# AVR32DU32 device description
Architecture: AVR8X; Family: AVR
Registers are 8-bit, read-write, reset 0x0 unless marked. A register's access mark holds for its fields unless they carry their own. Offsets are from the block's base; [hi:lo] are bit positions; {n}, {i} and the like mark numbered series; 'fields as' and 'values as' point back to an identical list.

## GPR — General Purpose Registers
Instances: GPR 0x001C
{0x0+i} GPR{i} reset not defined (i=0..3) — General Purpose Register {i}

## LOCK — Lockbits
Instances: LOCK 0x1040
0x00 KEY 32-bit reset 0x5CC5C55C — Lock Key Bits
  [31:0] KEY — Lock Key
    0x5CC5C55C=NOLOCK (No locks); 0xA33A3AA3=RWLOCK (Read and write lock)

## NVMCTRL — Non-volatile Memory Controller
Instances: NVMCTRL 0x1000
0x00 CTRLA — Control A
  [6:0] CMD — Command
    0=NONE (No Command); 1=NOOP (No Operation); 2=FLWR (Flash Write); 8=FLPER (Flash Page Erase); 9=FLMPER2 (Flash Multi-Page Erase 2 pages); 10=FLMPER4 (Flash Multi-Page Erase 4 pages); 11=FLMPER8 (Flash Multi-Page Erase 8 pages); 12=FLMPER16 (Flash Multi-Page Erase 16 pages); 13=FLMPER32 (Flash Multi-Page Erase 32 pages); 18=EEWR (EEPROM Write); 19=EEERWR (EEPROM Erase and Write); 24=EEBER (EEPROM Byte Erase); 25=EEMBER2 (EEPROM Multi-Byte Erase 2 bytes); 26=EEMBER4 (EEPROM Multi-Byte Erase 4 bytes); 27=EEMBER8 (EEPROM Multi-Byte Erase 8 bytes); 28=EEMBER16 (EEPROM Multi-Byte Erase 16 bytes); 29=EEMBER32 (EEPROM Multi-Byte Erase 32 bytes); 32=CHER (Chip Erase Command); 48=EECHER (EEPROM Erase Command)
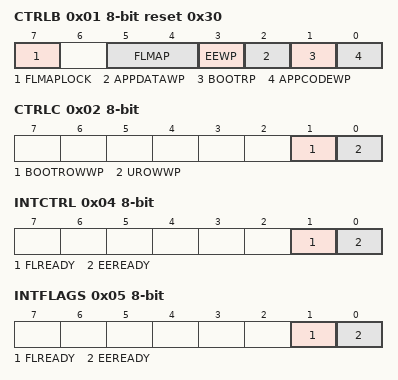
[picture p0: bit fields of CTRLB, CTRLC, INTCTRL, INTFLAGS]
0x01 CTRLB reset 0x30 — Control B
  [7] FLMAPLOCK — Flash Mapping Lock
  [5:4] FLMAP — Flash Mapping in Data space
    {v}=SECTION{v} (Flash section {v}) (v=0..3)
  [3] EEWP — EEPROM Write Protect
  [2] APPDATAWP — Application Data Write Protect
  [1] BOOTRP — Boot Read Protect
  [0] APPCODEWP — Application Code Write Protect
0x02 CTRLC — Control C
  [1] BOOTROWWP — Boot Row Write Protect
  [0] UROWWP — User Row Write Protect
0x04 INTCTRL — Interrupt Control
  [1] FLREADY — Flash Ready
  [0] EEREADY — EEPROM Ready
0x05 INTFLAGS — Interrupt Flags
  [1] FLREADY — Flash Ready
  [0] EEREADY — EEPROM Ready
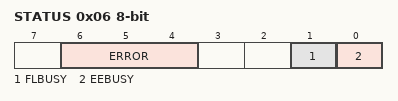
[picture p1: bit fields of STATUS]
0x06 STATUS ro
  [6:4] ERROR — Write error
    0=NOERROR; 1=INVALIDCMD (Write command not selected or not valid); 2=WRITEPROTECT (Write to section not allowed); 3=CMDCOLLISION (Selecting new write command while programming is ongoing)
  [1] FLBUSY — Flash busy
  [0] EEBUSY — EEPROM busy
0x08 DATA 32-bit
0x0C ADDR 32-bit reset not defined — Address

## PORT — I/O Ports
Instances: PORTA 0x0400, PORTC 0x0440, PORTD 0x0460, PORTF 0x04A0
0x00 DIR — Data Direction
0x01 DIRSET — Data Direction Set
0x02 DIRCLR — Data Direction Clear
0x03 DIRTGL — Data Direction Toggle
0x04 OUT — Output Value
0x05 OUTSET — Output Value Set
0x06 OUTCLR — Output Value Clear
0x07 OUTTGL — Output Value Toggle
0x08 IN — Input Value
0x09 INTFLAGS — Interrupt Flags
  [7:0] INT — Pin Interrupt Flag
0x0A PORTCTRL — Port Control
  [0] SRL — Slew Rate Limit Enable
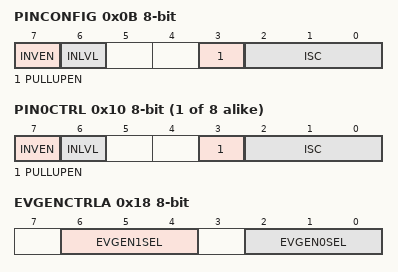
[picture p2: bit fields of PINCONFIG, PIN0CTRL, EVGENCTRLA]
0x0B PINCONFIG — Pin Control Config
  [7] INVEN — Inverted I/O Enable
  [6] INLVL — Input Level Select
    0=ST (Schmitt-Trigger input level); 1=TTL (TTL Input level)
  [3] PULLUPEN — Pullup enable
  [2:0] ISC — Input/Sense Configuration
    0=INTDISABLE (Interrupt disabled but input buffer enabled); 1=BOTHEDGES (Sense Both Edges); 2=RISING (Sense Rising Edge); 3=FALLING (Sense Falling Edge); 4=INPUT_DISABLE (Digital Input Buffer disabled); 5=LEVEL (Sense low Level)
0x0C PINCTRLUPD — Pin Control Update
0x0D PINCTRLSET — Pin Control Set
0x0E PINCTRLCLR — Pin Control Clear
{0x10+i} PIN{i}CTRL (i=0..7) — Pin {i} Control
  fields as PINCONFIG
0x18 EVGENCTRLA — Event Generation Control A
  [6:4] EVGEN1SEL — Event Generator 1 Select
    {v}=PIN{v} (Pin {v} used as event generator) (v=0..7)
  [2:0] EVGEN0SEL — Event Generator 0 Select
    {v}=PIN{v} (Pin {v} used as event generator) (v=0..7)

## PORTMUX — Port Multiplexer
Instances: PORTMUX 0x05E0
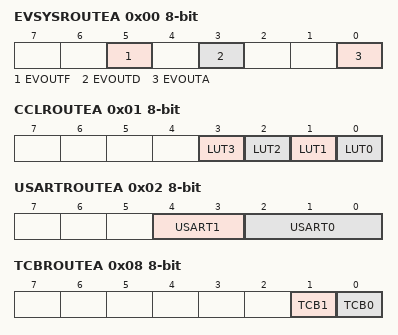
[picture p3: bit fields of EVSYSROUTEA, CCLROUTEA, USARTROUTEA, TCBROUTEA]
0x00 EVSYSROUTEA
  [5] EVOUTF — Event Output F
    0=DEFAULT (EVOUTF: PF2); 1=ALT1 (EVOUTF: PF7)
  [3] EVOUTD — Event Output D
    0=DEFAULT (EVOUTD: PD2); 1=ALT1 (EVOUTD: PD7)
  [0] EVOUTA — Event Output A
    0=DEFAULT (EVOUTA: PA2); 1=ALT1 (EVOUTA: PA7)
0x01 CCLROUTEA
  [3] LUT3 — CCL Look-Up Table 3 Signals
    0=DEFAULT (In: PF0, PF1, PF2, Out: PF3)
  [2] LUT2 — CCL Look-Up Table 2 Signals
    0=DEFAULT (In: PD0, PD1, PD2, Out: PD3); 1=ALT1 (In: PD0, PD1, PD2, Out: PD6)
  [1] LUT1 — CCL Look-Up Table 1 Signals
    0=DEFAULT (In: -, -, -, Out: PC3)
  [0] LUT0 — CCL Look-Up Table 0 Signals
    0=DEFAULT (In: PA0, PA1, PA2, Out: PA3); 1=ALT1 (In: PA0, PA1, PA2, Out: PA6)
0x02 USARTROUTEA
  [4:3] USART1 — USART1 Signals
    0=DEFAULT (Not connected to any pins); 2=ALT2 (TxD: PD6, RxD: PD7, XCK: -, XDIR: -)
  [2:0] USART0 — USART0 Signals
    0=DEFAULT (TxD: PA0, RxD: PA1, XCK: PA2, XDIR: PA3); 1=ALT1 (TxD: PA4, RxD: PA5, XCK: PA6, XDIR: PA7); 2=ALT2 (TxD: PA2, RxD: PA3, XCK: -, XDIR: -); 3=ALT3 (TxD: PD4, RxD: PD5, XCK: PD6, XDIR: PD7); 5=NONE (Not connected to any pins)
0x05 SPIROUTEA
  [2:0] SPI0 — SPI0 Signals
    0=DEFAULT (MOSI: PA4, MISO: PA5, SCK: PA6, SS: PA7); 4=ALT4 (MOSI: PD4, MISO: PD5, SCK: PD6, SS: PD7); 7=NONE (Not connected to any pins, SS set to 1)
0x06 TWIROUTEA
  [1:0] TWI0 — TWI0 Signals
    0=DEFAULT (SDA: PA2, SCL: PA3); 1=ALT1 (SDA: PA2, SCL: PA3); 3=ALT3 (SDA: PA0, SCL: PA1)
0x07 TCAROUTEA
  [2:0] TCA0 — TCA0 Signals
    0=PORTA (WOn: PA0, PA1, PA2, PA3, PA4, PA5); 2=PORTC (WOn: -, -, -, PC3, -, -); 3=PORTD (WOn: PD0, PD1, PD2, PD3, PD4, PD5); 5=PORTF (WOn: PF0, PF1, PF2, PF3, PF4, PF5)
0x08 TCBROUTEA
  [1] TCB1 — TCB1 Output
    0=DEFAULT (WO: PA3); 1=ALT1 (WO: PF5)
  [0] TCB0 — TCB0 Output
    0=DEFAULT (WO: PA2); 1=ALT1 (WO: PF4)
